# S1C31D01 register map
Vendor: Epson; Series: S1C31D01; File version: 1.00
CPU: CM0PLUS r0p1, little endian, MPU, no FPU, VTOR, 2 interrupt priority bits
Registers are 16-bit, read-write, reset 0x0 unless marked. A register's access mark holds for its fields unless they carry their own. Offsets are from the block's base; [hi:lo] are bit positions; {n}, {i} and the like mark numbered series; 'fields as' and 'values as' point back to an identical list.

## REMC3 — IR Remote Controller
Base 0x40000720
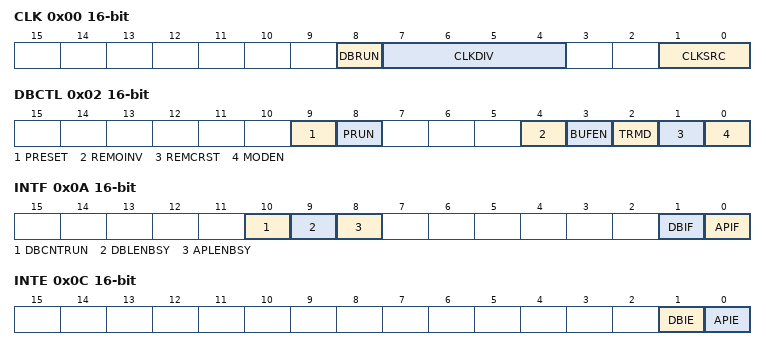
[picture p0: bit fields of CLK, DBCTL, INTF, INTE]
0x00 CLK — Clock Control Register
  [8] DBRUN — Enable clock on debug mode
    0=DISABLE; 1=ENABLE
  [7:4] CLKDIV — Clock division select
  [1:0] CLKSRC — Clock source select
    0=IOSC; 1=OSC1; 2=OSC3; 3=EXOSC
0x02 DBCTL — Data Bit Counter Control Register
  [9] PRESET write-1-sets — Data bit counter reset (Cleared by writing to the REMCRST register bit)
    on write: 0=NON (No effect); 1=RESET | on read: 0=NORMAL (Resetting finished or normal operation); 1=BUSY (Resetting in progress)
  [8] PRUN — Data bit counter run/stop control (Cleared by writing to the REMCRST register bit)
    on write: 0=STOP (Stop counting); 1=RUN (Start counting) | on read: 0=STOP (Idle); 1=RUN (Counting)
  [4] REMOINV — REMO invert
    0=NON_INVERT (Non-inverted); 1=INVERT (Inverted)
  [3] BUFEN — Buffer enable
    0=DISABLE; 1=ENABLE
  [2] TRMD — Data bit counter mode
    0=REPEAT (Repeat mode); 1=ONESHOT (One-shot mode)
  [1] REMCRST wo write-1-sets — Software Reset
    on write: 0=NON (No effect); 1=RESET (Issue software reset) | on read: 0=NORMAL (Software reset has finished (During normal operation)); 1=BUSY (Software reset is executing)
  [0] MODEN — REMC enable
    0=DISABLE; 1=ENABLE
0x04 DBCNT ro — Data Bit Counter Register (Cleared by writing to the REMCRST register bit)
  [15:0] DBCNT rw — Data bit counter
0x06 APLEN — Data bit Active Pulse Length Register
  [15:0] APLEN — Active pulse length
0x08 DBLEN — Data Bit Length Register
  [15:0] DBLEN — Data bit length
0x0A INTF — Status / Interrupt Flag Register
  [10] DBCNTRUN ro — Data bit counter running status (Cleared by writing to the REMCRST)
    0=IDLE; 1=RUN (Running (Counting))
  [9] DBLENBSY ro — DBLEN buffer busy
    0=READY (Transfer to the DBLEN buffer has completed); 1=BUSY (Transfer to the DBLEN buffer has not completed)
  [8] APLENBSY ro — APLEN buffer busy
    0=READY (Transfer to the APLEN buffer has completed); 1=BUSY (Transfer to the APLEN buffer has not completed)
  [1] DBIF ro write-1-clears — Data bit length interrupt flag
    0=NOT_OCCURED (No cause of interrupt occurred); 1=OCCURED (Cause of interrupt occurred)
  [0] APIF ro write-1-clears — Data bit length first part interrupt flag (Cleared by writing to the REMCRST register bit or Cleared by writing 1)
    values as DBIF
0x0C INTE — Interrupt Enable Register
  [1] DBIE — Data bit length interrupt enable
    0=DISABLE; 1=ENABLE
  [0] APIE — Data bit length first part interrupt enable
    0=DISABLE; 1=ENABLE
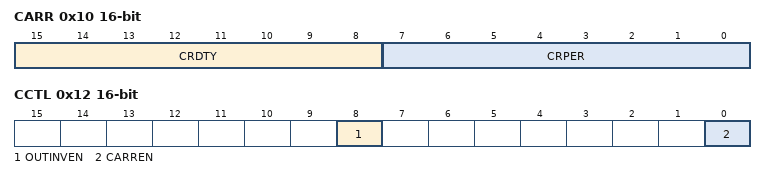
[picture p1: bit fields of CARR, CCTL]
0x10 CARR — Carrier Waveform Register
  [15:8] CRDTY — Carrier duty
  [7:0] CRPER — Carrier period
0x12 CCTL — Carrier Modulation Control Register
  [8] OUTINVEN — Output inversion enable
    0=NORMAL (Disable); 1=ENABLE (INVERT)
  [0] CARREN — Carrier modulation enable
    0=DISABLE; 1=ENABLE

## ADC12A_0 — 12 bit ADC controller
Base 0x400007A0
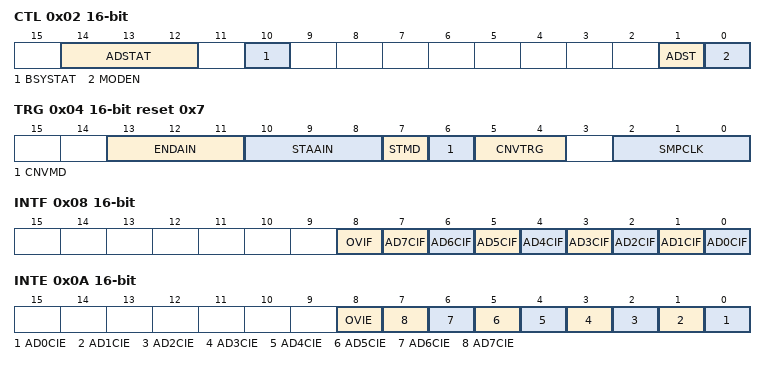
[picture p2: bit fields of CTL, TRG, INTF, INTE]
0x02 CTL — ADC Control Register
  [14:12] ADSTAT ro — ADC channel status
  [10] BSYSTAT ro — ADC busy status
    0=IDLE (ADC is Idle); 1=BUSY (ADC is Busy)
  [1] ADST — Conversion control
    0=STOP (Conversion control is stopped); 1=START (Conversion control is started/running)
  [0] MODEN — AD enable, ADCLK enable
    0=DISABLE (Disabled); 1=ENABLE (Enabled)
0x04 TRG reset 0x7 — A/D Converter Trigger/Channel select Register
  [13:11] ENDAIN — End channel select
  [10:8] STAAIN — Start channel select
  [7] STMD — Data store mode
  [6] CNVMD — Conversion store mode
    0=SINGLE; 1=CONTINUOUS
  [5:4] CNVTRG — Conversion trigger select
    0=SOFTWARE; 1=16BIT_TIMER; 3=ADTRG_PIN
  [2:0] SMPCLK — Sampling clock count
    {v}={v+4}CLK ({v+4} Clocks) (v=0..7)
0x06 CFG — ADC configuration register
  [1:0] VRANGE — Comparator input voltage range
    0=IQ (Conversion Disabled (IQ)); 1=4_8 (4.8 to 5.5V); 2=3_6 (3.6 to 5.5V); 3=1_8 (1.8 to 5.5V)
0x08 INTF — ADC interrupt flag register
  [8] OVIF write-1-clears — Overrun error interrupt flag
    0=NO_ERROR; 1=ERROR
  [n] AD{n}CIF write-1-clears (n=0..7) — Ch{n} conversion interrupt flag.
    0=NOT_COMPLETE (Conversion not complete); 1=COMPLETE (Conversion complete)
0x0A INTE — ADC interrupt enable
  [all] fields
    0=DISABLE (Disabled); 1=ENABLE (Enabled)
  [8] OVIE write-1-clears — Overrun interrupt enable
  [n] AD{n}CIE write-1-clears (n=0..7) — Ch{n} conversion interrupt enable
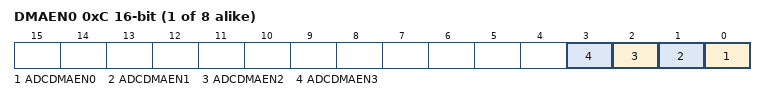
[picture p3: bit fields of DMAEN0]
{0xC+2i} DMAEN{i} (i=0..7) — DMA request enable
  [all] fields
    0=DISABLE (Disabled); 1=ENABLE (Enabled)
  [n] ADCDMAEN{n} (n=0..3) — DMA ch{n} enable
0x1C ADD ro — ADC Result Register
  [15:0] ADD — Conversion data
